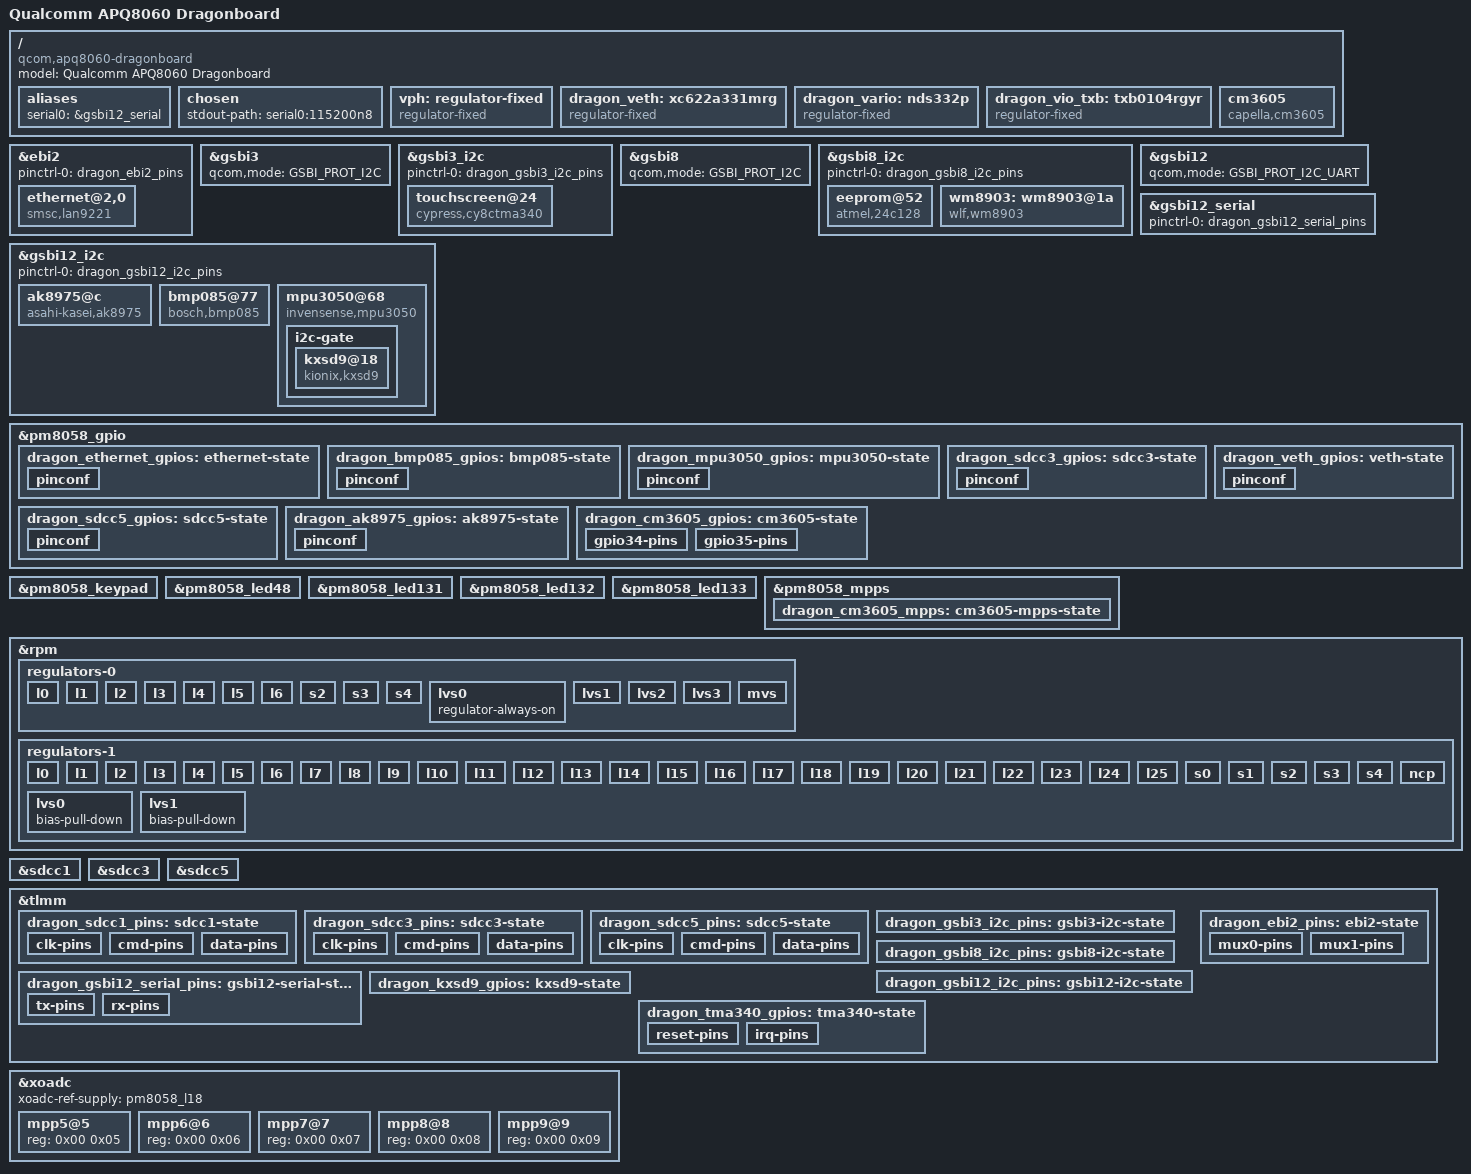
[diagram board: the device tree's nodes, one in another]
#include <dt-bindings/input/input.h>
#include <dt-bindings/gpio/gpio.h>
#include <dt-bindings/leds/common.h>
#include <dt-bindings/pinctrl/qcom,pmic-gpio.h>
#include <dt-bindings/pinctrl/qcom,pmic-mpp.h>
#include "qcom-msm8660.dtsi"
/ {
	model = "Qualcomm APQ8060 Dragonboard";
	compatible = "qcom,apq8060-dragonboard", "qcom,msm8660";
	aliases {
		serial0 = &gsbi12_serial;
	};
	chosen {
		stdout-path = "serial0:115200n8";
	};
	vph: regulator-fixed {
		compatible = "regulator-fixed";
		regulator-min-microvolt = <3700000>;
		regulator-max-microvolt = <3700000>;
		regulator-name = "VPH";
		regulator-type = "voltage";
		regulator-always-on;
		regulator-boot-on;
	};
	dragon_veth: xc622a331mrg {
		compatible = "regulator-fixed";
		regulator-name = "XC6222A331MR-G";
		regulator-min-microvolt = <3300000>;
		regulator-max-microvolt = <3300000>;
		vin-supply = <&vph>;
		gpio = <&pm8058_gpio 40 GPIO_ACTIVE_HIGH>;
		enable-active-high;
		pinctrl-names = "default";
		pinctrl-0 = <&dragon_veth_gpios>;
		regulator-always-on;
	};
	dragon_vario: nds332p {
		compatible = "regulator-fixed";
		regulator-name = "NDS332P";
		regulator-min-microvolt = <1800000>;
		regulator-max-microvolt = <1800000>;
		vin-supply = <&pm8058_s3>;
	};
	dragon_vio_txb: txb0104rgyr {
		compatible = "regulator-fixed";
		regulator-name = "Dragon SDCC levelshifter";
		vin-supply = <&pm8058_l14>;
		regulator-always-on;
	};
	cm3605 {
		compatible = "capella,cm3605";
		vdd-supply = <&pm8058_l14>;  
		aset-gpios = <&pm8058_gpio 35 GPIO_ACTIVE_LOW>;
		capella,aset-resistance-ohms = <100000>;
		interrupts-extended = <&pm8058_gpio 34 IRQ_TYPE_EDGE_BOTH>;
		io-channels = <&xoadc 0x00 0x05>;
		io-channel-names = "aout";
		pinctrl-names = "default";
		pinctrl-0 = <&dragon_cm3605_gpios>, <&dragon_cm3605_mpps>;
	};
};
&ebi2 {
	pinctrl-names = "default";
	pinctrl-0 = <&dragon_ebi2_pins>;
	status = "okay";
	ethernet@2,0 {
		compatible = "smsc,lan9221", "smsc,lan9115";
		reg = <2 0x0 0x100>;
		interrupts-extended = <&pm8058_gpio 7 IRQ_TYPE_EDGE_FALLING>,
				    <&tlmm 29 IRQ_TYPE_EDGE_RISING>;
		reset-gpios = <&tlmm 30 GPIO_ACTIVE_LOW>;
		vdd33a-supply = <&dragon_veth>;
		vddvario-supply = <&dragon_vario>;
		pinctrl-names = "default";
		pinctrl-0 = <&dragon_ethernet_gpios>;
		phy-mode = "mii";
		reg-io-width = <2>;
		smsc,force-external-phy;
		smsc,irq-push-pull;
		qcom,xmem-recovery-cycles = <0>;
		qcom,xmem-write-hold-cycles = <3>;
		qcom,xmem-write-delta-cycles = <31>;
		qcom,xmem-read-delta-cycles = <28>;
		qcom,xmem-write-wait-cycles = <9>;
		qcom,xmem-read-wait-cycles = <9>;
	};
};
&gsbi3 {
	qcom,mode = <GSBI_PROT_I2C>;
	status = "okay";
};
&gsbi3_i2c {
	pinctrl-names = "default";
	pinctrl-0 = <&dragon_gsbi3_i2c_pins>;
	status = "okay";
	touchscreen@24 {
		compatible = "cypress,cy8ctma340";
		reg = <0x24>;
		clock-frequency = <400000>;
		interrupt-parent = <&tlmm>;
		interrupts = <61 IRQ_TYPE_EDGE_FALLING>;
		vcpin-supply = <&pm8058_l16>;
		vdd-supply = <&pm8901_l2>;
		reset-gpios = <&tlmm 58 GPIO_ACTIVE_LOW>;
		touchscreen-size-x = <480>;
		touchscreen-size-y = <800>;
		active-interval-ms = <0>;
		touch-timeout-ms = <255>;
		lowpower-interval-ms = <10>;
		bootloader-key = /bits/ 8 <0x00 0x01 0x02 0x03 0x04 0x05 0x06 0x07>;
		pinctrl-names = "default";
		pinctrl-0 = <&dragon_tma340_gpios>;
	};
};
&gsbi8 {
	qcom,mode = <GSBI_PROT_I2C>;
	status = "okay";
};
&gsbi8_i2c {
	pinctrl-names = "default";
	pinctrl-0 = <&dragon_gsbi8_i2c_pins>;
	status = "okay";
	eeprom@52 {
		compatible = "atmel,24c128";
		reg = <0x52>;
		vcc-supply = <&pm8058_s3>;
		pagesize = <64>;
	};
	wm8903: wm8903@1a {
		compatible = "wlf,wm8903";
		reg = <0x1a>;
		AVDD-supply = <&pm8058_l16>;
		CPVDD-supply = <&pm8058_l16>;
		DBVDD-supply = <&pm8058_s3>;
		DCVDD-supply = <&pm8058_l0>;
		gpio-controller;
		#gpio-cells = <2>;
		micdet-cfg = <0>;
		micdet-delay = <100>;
		gpio-cfg = <0xffffffff 0xffffffff 0 0xffffffff 0xffffffff>;
	};
};
&gsbi12 {
	qcom,mode = <GSBI_PROT_I2C_UART>;
	status = "okay";
};
&gsbi12_serial {
	pinctrl-names = "default";
	pinctrl-0 = <&dragon_gsbi12_serial_pins>;
	status = "okay";
};
&gsbi12_i2c {
	pinctrl-names = "default";
	pinctrl-0 = <&dragon_gsbi12_i2c_pins>;
	status = "okay";
	ak8975@c {
		compatible = "asahi-kasei,ak8975";
		reg = <0x0c>;
		interrupt-parent = <&pm8058_gpio>;
		interrupts = <33 IRQ_TYPE_EDGE_RISING>;
		pinctrl-names = "default";
		pinctrl-0 = <&dragon_ak8975_gpios>;
		vid-supply = <&pm8058_lvs0>;  
		vdd-supply = <&pm8058_l14>;  
	};
	bmp085@77 {
		compatible = "bosch,bmp085";
		reg = <0x77>;
		interrupt-parent = <&pm8058_gpio>;
		interrupts = <16 IRQ_TYPE_EDGE_RISING>;
		reset-gpios = <&tlmm 86 GPIO_ACTIVE_LOW>;
		pinctrl-names = "default";
		pinctrl-0 = <&dragon_bmp085_gpios>;
		vddd-supply = <&pm8058_lvs0>;  
		vdda-supply = <&pm8058_l14>;  
	};
	mpu3050@68 {
		compatible = "invensense,mpu3050";
		reg = <0x68>;
		interrupts-extended = <&pm8058_gpio 17 IRQ_TYPE_EDGE_FALLING>;
		pinctrl-names = "default";
		pinctrl-0 = <&dragon_mpu3050_gpios>;
		vlogic-supply = <&pm8058_lvs0>;  
		vdd-supply = <&pm8058_l14>;  
		i2c-gate {
			#address-cells = <1>;
			#size-cells = <0>;
			kxsd9@18 {
				compatible = "kionix,kxsd9";
				reg = <0x18>;
				interrupt-parent = <&tlmm>;
				interrupts = <57 IRQ_TYPE_EDGE_FALLING>;
				pinctrl-names = "default";
				pinctrl-0 = <&dragon_kxsd9_gpios>;
				iovdd-supply = <&pm8058_lvs0>;  
				vdd-supply = <&pm8058_l14>;  
			};
		};
	};
};
&pm8058_gpio {
	dragon_ethernet_gpios: ethernet-state {
		pinconf {
			pins = "gpio7";
			function = "normal";
			input-enable;
			bias-disable;
			power-source = <PM8058_GPIO_S3>;
		};
	};
	dragon_bmp085_gpios: bmp085-state {
		pinconf {
			pins = "gpio16";
			function = "normal";
			input-enable;
			bias-disable;
			power-source = <PM8058_GPIO_S3>;
		};
	};
	dragon_mpu3050_gpios: mpu3050-state {
		pinconf {
			pins = "gpio17";
			function = "normal";
			input-enable;
			bias-disable;
			power-source = <PM8058_GPIO_S3>;
		};
	};
	dragon_sdcc3_gpios: sdcc3-state {
		pinconf {
			pins = "gpio22";
			function = "normal";
			input-enable;
			bias-disable;
			power-source = <PM8058_GPIO_S3>;
		};
	};
	dragon_sdcc5_gpios: sdcc5-state {
		pinconf {
			pins = "gpio26";
			function = "normal";
			input-enable;
			bias-pull-up;
			qcom,pull-up-strength = <PMIC_GPIO_PULL_UP_30>;
			power-source = <PM8058_GPIO_S3>;
		};
	};
	dragon_ak8975_gpios: ak8975-state {
		pinconf {
			pins = "gpio33";
			function = "normal";
			input-enable;
			bias-disable;
			power-source = <PM8058_GPIO_S3>;
		};
	};
	dragon_cm3605_gpios: cm3605-state {
		gpio34-pins {
			pins = "gpio34";
			function = "normal";
			input-enable;
			bias-disable;
			power-source = <PM8058_GPIO_S3>;
		};
		gpio35-pins {
			pins = "gpio35";
			function = "normal";
			output-high;
			bias-disable;
			power-source = <PM8058_GPIO_S3>;
		};
	};
	dragon_veth_gpios: veth-state {
		pinconf {
			pins = "gpio40";
			function = "normal";
			bias-disable;
			drive-push-pull;
		};
	};
};
&pm8058_keypad {
	linux,keymap = <
		MATRIX_KEY(0, 0, KEY_MENU)
		MATRIX_KEY(0, 2, KEY_1)
		MATRIX_KEY(0, 3, KEY_4)
		MATRIX_KEY(0, 4, KEY_7)
		MATRIX_KEY(1, 0, KEY_UP)
		MATRIX_KEY(1, 1, KEY_LEFT)
		MATRIX_KEY(1, 2, KEY_DOWN)
		MATRIX_KEY(1, 3, KEY_5)
		MATRIX_KEY(1, 3, KEY_8)
		MATRIX_KEY(2, 0, KEY_HOME)
		MATRIX_KEY(2, 1, KEY_REPLY)
		MATRIX_KEY(2, 2, KEY_2)
		MATRIX_KEY(2, 3, KEY_6)
		MATRIX_KEY(3, 0, KEY_VOLUMEUP)
		MATRIX_KEY(3, 1, KEY_RIGHT)
		MATRIX_KEY(3, 2, KEY_3)
		MATRIX_KEY(3, 3, KEY_9)
		MATRIX_KEY(3, 4, KEY_SWITCHVIDEOMODE)
		MATRIX_KEY(4, 0, KEY_VOLUMEDOWN)
		MATRIX_KEY(4, 1, KEY_BACK)
		MATRIX_KEY(4, 2, KEY_CAMERA)
		MATRIX_KEY(4, 3, KEY_KBDILLUMTOGGLE)
	>;
	keypad,num-rows = <6>;
	keypad,num-columns = <5>;
};
&pm8058_led48 {
	label = "pm8058:infrared:proximitysensor";
	default-state = "off";
	linux,default-trigger = "cm3605";
	status = "okay";
};
&pm8058_led131 {
	label = "pm8058:red";
	color = <LED_COLOR_ID_RED>;
	default-state = "off";
	status = "okay";
};
&pm8058_led132 {
	label = "pm8058:yellow";
	color = <LED_COLOR_ID_YELLOW>;
	default-state = "off";
	linux,default-trigger = "mmc0";
	status = "okay";
};
&pm8058_led133 {
	label = "pm8058:green";
	function = LED_FUNCTION_HEARTBEAT;
	color = <LED_COLOR_ID_GREEN>;
	default-state = "on";
	linux,default-trigger = "heartbeat";
	status = "okay";
};
&pm8058_mpps {
	dragon_cm3605_mpps: cm3605-mpps-state {
		pins = "mpp5";
		function = "analog";
		input-enable;
		bias-high-impedance;
		qcom,amux-route = <PMIC_MPP_AMUX_ROUTE_CH5>;
		power-source = <PM8058_GPIO_S3>;
	};
};
&rpm {
	regulators-0 {
		vdd_l0-supply = <&pm8901_s4>;
		vdd_l1-supply = <&vph>;
		vdd_l2-supply = <&vph>;
		vdd_l3-supply = <&vph>;
		vdd_l4-supply = <&vph>;
		vdd_l5-supply = <&vph>;
		vdd_l6-supply = <&vph>;
		vdd_s2-supply = <&vph>;
		vdd_s3-supply = <&vph>;
		vdd_s4-supply = <&vph>;
		lvs0_in-supply = <&pm8058_s3>;
		lvs1_in-supply = <&pm8901_s4>;
		lvs2_in-supply = <&pm8058_l0>;
		lvs3_in-supply = <&pm8058_s2>;
		mvs_in-supply = <&pm8058_s3>;
		l0 {
			regulator-min-microvolt = <1200000>;
			regulator-max-microvolt = <1200000>;
			bias-pull-down;
		};
		l1 {
			regulator-min-microvolt = <3300000>;
			regulator-max-microvolt = <3300000>;
			bias-pull-down;
		};
		l2 {
			regulator-min-microvolt = <3300000>;
			regulator-max-microvolt = <3300000>;
			bias-pull-down;
		};
		l3 {
			regulator-min-microvolt = <3300000>;
			regulator-max-microvolt = <3300000>;
			bias-pull-down;
		};
		l4 {
			regulator-min-microvolt = <2600000>;
			regulator-max-microvolt = <2600000>;
			bias-pull-down;
		};
		l5 {
			regulator-min-microvolt = <2850000>;
			regulator-max-microvolt = <2850000>;
			bias-pull-down;
		};
		l6 {
			regulator-min-microvolt = <2200000>;
			regulator-max-microvolt = <2200000>;
			bias-pull-down;
		};
		s2 {
			regulator-min-microvolt = <1300000>;
			regulator-max-microvolt = <1300000>;
			qcom,switch-mode-frequency = <1600000>;
			bias-pull-down;
		};
		s3 {
			regulator-min-microvolt = <1100000>;
			regulator-max-microvolt = <1100000>;
			qcom,switch-mode-frequency = <1600000>;
			bias-pull-down;
		};
		s4 {
			regulator-min-microvolt = <1225000>;
			regulator-max-microvolt = <1225000>;
			qcom,switch-mode-frequency = <1600000>;
			bias-pull-down;
		};
		lvs0 {
			regulator-always-on;
		};
		lvs1 { };
		lvs2 { };
		lvs3 { };
		mvs { };
	};
	regulators-1 {
		vdd_l0_l1_lvs-supply = <&pm8058_s3>;
		vdd_l2_l11_l12-supply = <&vph>;
		vdd_l3_l4_l5-supply = <&vph>;
		vdd_l6_l7-supply = <&vph>;
		vdd_l8-supply = <&vph>;
		vdd_l9-supply = <&vph>;
		vdd_l10-supply = <&vph>;
		vdd_l13_l16-supply = <&pm8058_s4>;
		vdd_l14_l15-supply = <&vph>;
		vdd_l17_l18-supply = <&vph>;
		vdd_l19_l20-supply = <&vph>;
		vdd_l21-supply = <&pm8058_s3>;
		vdd_l22-supply = <&pm8058_s3>;
		vdd_l23_l24_l25-supply = <&pm8058_s3>;
		vdd_s0-supply = <&vph>;
		vdd_s1-supply = <&vph>;
		vdd_s2-supply = <&vph>;
		vdd_s3-supply = <&vph>;
		vdd_s4-supply = <&vph>;
		vdd_ncp-supply = <&vph>;
		l0 {
			regulator-min-microvolt = <1200000>;
			regulator-max-microvolt = <1200000>;
			bias-pull-down;
		};
		l1 {
			regulator-min-microvolt = <1200000>;
			regulator-max-microvolt = <1200000>;
			bias-pull-down;
		};
		l2 {
			regulator-min-microvolt = <1800000>;
			regulator-max-microvolt = <2600000>;
			bias-pull-down;
		};
		l3 {
			regulator-min-microvolt = <1800000>;
			regulator-max-microvolt = <1800000>;
			bias-pull-down;
		};
		l4 {
			regulator-min-microvolt = <2850000>;
			regulator-max-microvolt = <2850000>;
			bias-pull-down;
		};
		l5 {
			regulator-min-microvolt = <2850000>;
			regulator-max-microvolt = <2850000>;
			bias-pull-down;
		};
		l6 {
			regulator-min-microvolt = <3000000>;
			regulator-max-microvolt = <3600000>;
			bias-pull-down;
		};
		l7 {
			regulator-min-microvolt = <1800000>;
			regulator-max-microvolt = <1800000>;
			bias-pull-down;
		};
		l8 {
			regulator-min-microvolt = <2900000>;
			regulator-max-microvolt = <3050000>;
			bias-pull-down;
		};
		l9 {
			regulator-min-microvolt = <1800000>;
			regulator-max-microvolt = <1800000>;
			bias-pull-down;
		};
		l10 {
			regulator-min-microvolt = <2600000>;
			regulator-max-microvolt = <2600000>;
			bias-pull-down;
		};
		l11 {
			regulator-min-microvolt = <1500000>;
			regulator-max-microvolt = <1500000>;
			bias-pull-down;
		};
		l12 {
			regulator-min-microvolt = <2900000>;
			regulator-max-microvolt = <2900000>;
			bias-pull-down;
		};
		l13 {
			regulator-min-microvolt = <2050000>;
			regulator-max-microvolt = <2050000>;
			bias-pull-down;
		};
		l14 {
			regulator-min-microvolt = <2850000>;
			regulator-max-microvolt = <2850000>;
		};
		l15 {
			regulator-min-microvolt = <2850000>;
			regulator-max-microvolt = <2850000>;
			bias-pull-down;
		};
		l16 {
			regulator-min-microvolt = <1800000>;
			regulator-max-microvolt = <1800000>;
			bias-pull-down;
			regulator-always-on;
		};
		l17 {
			regulator-min-microvolt = <2600000>;
			regulator-max-microvolt = <2600000>;
			bias-pull-down;
		};
		l18 {
			regulator-min-microvolt = <2200000>;
			regulator-max-microvolt = <2200000>;
			bias-pull-down;
		};
		l19 {
			regulator-min-microvolt = <2500000>;
			regulator-max-microvolt = <2500000>;
			bias-pull-down;
		};
		l20 {
			regulator-min-microvolt = <1800000>;
			regulator-max-microvolt = <1800000>;
			bias-pull-down;
		};
		l21 {
			regulator-min-microvolt = <1200000>;
			regulator-max-microvolt = <1200000>;
			bias-pull-down;
			regulator-always-on;
		};
		l22 {
			regulator-min-microvolt = <1150000>;
			regulator-max-microvolt = <1150000>;
			bias-pull-down;
		};
		l23 {
			regulator-min-microvolt = <1200000>;
			regulator-max-microvolt = <1200000>;
			bias-pull-down;
		};
		l24 {
			regulator-min-microvolt = <1200000>;
			regulator-max-microvolt = <1200000>;
			bias-pull-down;
		};
		l25 {
			regulator-min-microvolt = <1200000>;
			regulator-max-microvolt = <1200000>;
			bias-pull-down;
		};
		s0 {
			regulator-min-microvolt = <1100000>;
			regulator-max-microvolt = <1100000>;
			qcom,switch-mode-frequency = <1600000>;
			bias-pull-down;
		};
		s1 {
			regulator-min-microvolt = <1100000>;
			regulator-max-microvolt = <1100000>;
			qcom,switch-mode-frequency = <1600000>;
			bias-pull-down;
		};
		s2 {
			regulator-min-microvolt = <1200000>;
			regulator-max-microvolt = <1400000>;
			qcom,switch-mode-frequency = <1600000>;
			bias-pull-down;
		};
		s3 {
			regulator-min-microvolt = <1800000>;
			regulator-max-microvolt = <1800000>;
			qcom,switch-mode-frequency = <1600000>;
			regulator-always-on;
			bias-pull-down;
		};
		s4 {
			regulator-min-microvolt = <2200000>;
			regulator-max-microvolt = <2200000>;
			qcom,switch-mode-frequency = <1600000>;
			regulator-always-on;
			bias-pull-down;
		};
		lvs0 {
			bias-pull-down;
		};
		lvs1 {
			bias-pull-down;
		};
		ncp {
			regulator-min-microvolt = <1800000>;
			regulator-max-microvolt = <1800000>;
			qcom,switch-mode-frequency = <1600000>;
		};
	};
};
&sdcc1 {
	pinctrl-names = "default";
	pinctrl-0 = <&dragon_sdcc1_pins>;
	vmmc-supply = <&pm8901_l5>;
	vqmmc-supply = <&pm8901_lvs0>;
	status = "okay";
};
&sdcc3 {
	pinctrl-names = "default";
	pinctrl-0 = <&dragon_sdcc3_pins>, <&dragon_sdcc3_gpios>;
	cd-gpios = <&pm8058_gpio 22 GPIO_ACTIVE_LOW>;
	wp-gpios = <&tlmm 110 GPIO_ACTIVE_HIGH>;
	vmmc-supply = <&pm8058_l14>;
	status = "okay";
};
&sdcc5 {
	pinctrl-names = "default";
	pinctrl-0 = <&dragon_sdcc5_pins>, <&dragon_sdcc5_gpios>;
	cd-gpios = <&pm8058_gpio 26 GPIO_ACTIVE_LOW>;
	wp-gpios = <&tlmm 106 GPIO_ACTIVE_HIGH>;
	vmmc-supply = <&pm8058_l14>;
	vqmmc-supply = <&dragon_vio_txb>;
	status = "okay";
};
&tlmm {
	dragon_sdcc1_pins: sdcc1-state {
		clk-pins {
			pins = "gpio167";  
			function = "sdc1";
			drive-strength = <16>;
			bias-disable;
		};
		cmd-pins {
			pins = "gpio168";  
			function = "sdc1";
			drive-strength = <10>;
			bias-pull-up;
		};
		data-pins {
			pins = "gpio159", "gpio160", "gpio161", "gpio162",
			     "gpio163", "gpio164", "gpio165", "gpio166";
			function = "sdc1";
			drive-strength = <10>;
			bias-pull-up;
		};
	};
	dragon_sdcc3_pins: sdcc3-state {
		clk-pins {
			pins = "sdc3_clk";
			drive-strength = <8>;
			bias-disable;
		};
		cmd-pins {
			pins = "sdc3_cmd";
			drive-strength = <8>;
			bias-pull-up;
		};
		data-pins {
			pins = "sdc3_data";
			drive-strength = <8>;
			bias-pull-up;
		};
	};
	dragon_sdcc5_pins: sdcc5-state {
		clk-pins {
			pins = "gpio97";  
			function = "sdc5";
			drive-strength = <16>;
			bias-disable;
		};
		cmd-pins {
			pins = "gpio95";  
			function = "sdc5";
			drive-strength = <10>;
			bias-pull-up;
		};
		data-pins {
			pins = "gpio96", "gpio98", "gpio99", "gpio100";
			function = "sdc5";
			drive-strength = <10>;
			bias-pull-up;
		};
	};
	dragon_gsbi3_i2c_pins: gsbi3-i2c-state {
		pins = "gpio43", "gpio44";
		function = "gsbi3";
		drive-strength = <8>;
		bias-disable;
	};
	dragon_gsbi8_i2c_pins: gsbi8-i2c-state {
		pins = "gpio64", "gpio65";
		function = "gsbi8";
		drive-strength = <16>;
		bias-disable;
	};
	dragon_gsbi12_i2c_pins: gsbi12-i2c-state {
		pins = "gpio115", "gpio116";
		function = "gsbi12";
		drive-strength = <16>;
		bias-disable;
	};
	dragon_gsbi12_serial_pins: gsbi12-serial-state {
		tx-pins {
			pins = "gpio117";
			function = "gsbi12";
			drive-strength = <8>;
			bias-disable;
		};
		rx-pins {
			pins = "gpio118";
			function = "gsbi12";
			drive-strength = <2>;
			bias-pull-up;
		};
	};
	dragon_ebi2_pins: ebi2-state {
		mux0-pins {
			pins =
			    "gpio40",  
			    "gpio134";  
			function = "ebi2cs";
		};
		mux1-pins {
			pins =
			    "gpio123", "gpio124", "gpio125", "gpio126",
			    "gpio127", "gpio128", "gpio129", "gpio130",
			    "gpio135", "gpio136", "gpio137", "gpio138",
			    "gpio139", "gpio140", "gpio141", "gpio142",
			    "gpio143", "gpio144", "gpio145", "gpio146",
			    "gpio147", "gpio148", "gpio149", "gpio150",
			    "gpio151",  
			    "gpio153",  
			    "gpio157";  
			function = "ebi2";
		};
	};
	dragon_kxsd9_gpios: kxsd9-state {
		pins = "gpio57";  
		function = "gpio";
		bias-pull-up;
	};
	dragon_tma340_gpios: tma340-state {
		reset-pins {
			pins = "gpio58";
			function = "gpio";
			drive-strength = <6>;
			bias-disable;
		};
		irq-pins {
			pins = "gpio61";  
			function = "gpio";
			drive-strength = <2>;
			bias-pull-up;
		};
	};
};
&xoadc {
	xoadc-ref-supply = <&pm8058_l18>;
	mpp5@5 {
		reg = <0x00 0x05>;
	};
	mpp6@6 {
		reg = <0x00 0x06>;
	};
	mpp7@7 {
		reg = <0x00 0x07>;
	};
	mpp8@8 {
		reg = <0x00 0x08>;
	};
	mpp9@9 {
		reg = <0x00 0x09>;
	};
};
